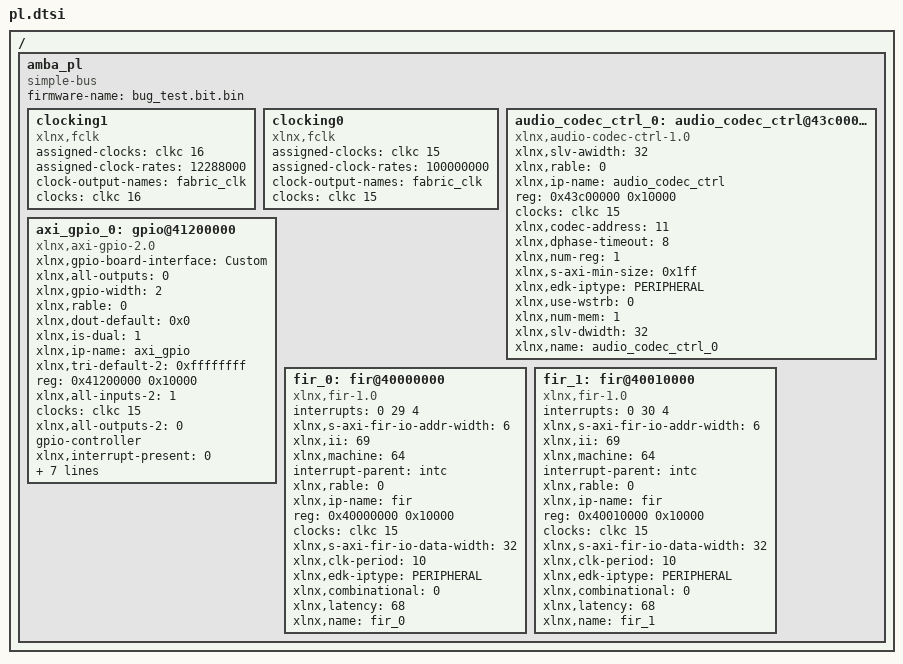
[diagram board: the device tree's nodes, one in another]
/ {
	amba_pl: amba_pl {
		ranges;
		compatible = "simple-bus";
		#address-cells = <1>;
		#size-cells = <1>;
		firmware-name = "bug_test.bit.bin";
		clocking1: clocking1 {
			compatible = "xlnx,fclk";
			assigned-clocks = <&clkc 16>;
			assigned-clock-rates = <12288000>;
			#clock-cells = <0>;
			clock-output-names = "fabric_clk";
			clocks = <&clkc 16>;
		};
		clocking0: clocking0 {
			compatible = "xlnx,fclk";
			assigned-clocks = <&clkc 15>;
			assigned-clock-rates = <100000000>;
			#clock-cells = <0>;
			clock-output-names = "fabric_clk";
			clocks = <&clkc 15>;
		};
		audio_codec_ctrl_0: audio_codec_ctrl@43c00000 {
			compatible = "xlnx,audio-codec-ctrl-1.0";
			xlnx,slv-awidth = <32>;
			xlnx,rable = <0>;
			xlnx,ip-name = "audio_codec_ctrl";
			reg = <0x43c00000 0x10000>;
			clocks = <&clkc 15>;
			xlnx,codec-address = "11";
			xlnx,dphase-timeout = <8>;
			xlnx,num-reg = <1>;
			xlnx,s-axi-min-size = <0x1ff>;
			xlnx,edk-iptype = "PERIPHERAL";
			xlnx,use-wstrb = <0>;
			xlnx,num-mem = <1>;
			status = "okay";
			xlnx,slv-dwidth = <32>;
			clock-names = "s_axi_aclk";
			xlnx,name = "audio_codec_ctrl_0";
		};
		axi_gpio_0: gpio@41200000 {
			xlnx,gpio-board-interface = "Custom";
			compatible = "xlnx,axi-gpio-2.0" , "xlnx,xps-gpio-1.00.a";
			xlnx,all-outputs = <0>;
			#gpio-cells = <2>;
			xlnx,gpio-width = <2>;
			xlnx,rable = <0>;
			xlnx,dout-default = <0x0>;
			xlnx,is-dual = <1>;
			xlnx,ip-name = "axi_gpio";
			xlnx,tri-default-2 = <0xffffffff>;
			reg = <0x41200000 0x10000>;
			xlnx,all-inputs-2 = <1>;
			clocks = <&clkc 15>;
			xlnx,all-outputs-2 = <0>;
			gpio-controller;
			xlnx,interrupt-present = <0>;
			xlnx,gpio2-board-interface = "Custom";
			xlnx,edk-iptype = "PERIPHERAL";
			xlnx,dout-default-2 = <0x0>;
			status = "okay";
			xlnx,gpio2-width = <1>;
			clock-names = "s_axi_aclk";
			xlnx,tri-default = <0xffffffff>;
			xlnx,name = "axi_gpio_0";
			xlnx,all-inputs = <0>;
		};
		fir_0: fir@40000000 {
			interrupts = < 0 29 4 >;
			compatible = "xlnx,fir-1.0";
			xlnx,s-axi-fir-io-addr-width = <6>;
			xlnx,ii = <69>;
			xlnx,machine = <64>;
			interrupt-parent = <&intc>;
			xlnx,rable = <0>;
			xlnx,ip-name = "fir";
			reg = <0x40000000 0x10000>;
			clocks = <&clkc 15>;
			xlnx,s-axi-fir-io-data-width = <32>;
			xlnx,clk-period = <10>;
			xlnx,edk-iptype = "PERIPHERAL";
			status = "okay";
			clock-names = "ap_clk";
			interrupt-names = "interrupt";
			xlnx,combinational = <0>;
			xlnx,latency = <68>;
			xlnx,name = "fir_0";
		};
		fir_1: fir@40010000 {
			interrupts = < 0 30 4 >;
			compatible = "xlnx,fir-1.0";
			xlnx,s-axi-fir-io-addr-width = <6>;
			xlnx,ii = <69>;
			xlnx,machine = <64>;
			interrupt-parent = <&intc>;
			xlnx,rable = <0>;
			xlnx,ip-name = "fir";
			reg = <0x40010000 0x10000>;
			clocks = <&clkc 15>;
			xlnx,s-axi-fir-io-data-width = <32>;
			xlnx,clk-period = <10>;
			xlnx,edk-iptype = "PERIPHERAL";
			status = "okay";
			clock-names = "ap_clk";
			interrupt-names = "interrupt";
			xlnx,combinational = <0>;
			xlnx,latency = <68>;
			xlnx,name = "fir_1";
		};
	};
};
